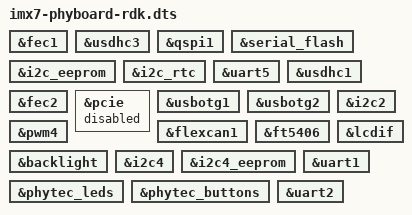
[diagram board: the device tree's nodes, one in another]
/*
 * Copyright (C) 2015 PHYTEC America, LLC
 *
 * This program is free software; you can redistribute it and/or modify
 * it under the terms of the GNU General Public License version 2 as
 * published by the Free Software Foundation.
 */
/dts-v1/;

#include "imx7-phycore-som.dtsi"
#include "imx7-pba-c-09.dtsi"
#include "imx7-peb-eval-02.dtsi"

/**** SOM - PCM-061 ****/

&fec1 {
	status = "okay";
};

/* eMMC */
&usdhc3 {
	status = "okay";
};

&qspi1 {
	status = "okay";
};

&serial_flash {
	status = "okay";
};

&i2c_eeprom {
	status = "okay";
};

&i2c_rtc {
	status = "okay";
};

/**** Carrier Board - PBA-C-09 ****/

&uart5 {
	status = "okay";
};

&usdhc1 {
	status = "okay";
};

&fec2 {
	status = "okay";
};

&pcie {
	status = "disabled";
};

/* Host mode */
&usbotg1 {
	status = "okay";
};

/* OTG mode */
&usbotg2 {
	status = "okay";
};

&flexcan1 {
	status = "okay";
};

/* PEB-AV-02: touch controller ft5406, LCD and PWM backlight control */
&i2c2 {
	status = "okay";
};

&ft5406 {
	status = "okay";
};

&lcdif {
	status = "okay";
};

&pwm4 {
	status = "okay";
};

&backlight {
	status = "okay";
};

/* Interfaces on PEB-EVAL-02 */

&i2c4 {
	status = "okay";
};

&i2c4_eeprom {
	status = "okay";
};

&phytec_leds {
	status = "okay";
};

&phytec_buttons {
	status = "okay";
};

&uart1 {
	status = "okay";
};

&uart2 {
	status = "okay";
};
